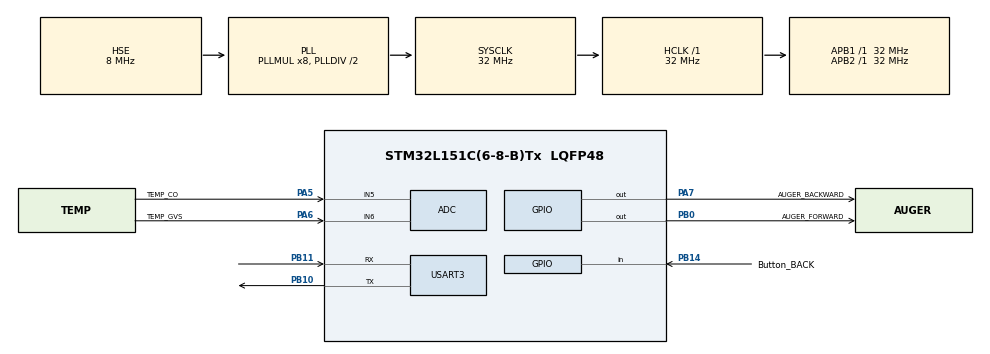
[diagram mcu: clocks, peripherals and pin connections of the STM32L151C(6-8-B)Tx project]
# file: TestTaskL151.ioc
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ADC.Channel-0\#ChannelRegularConversion=ADC_CHANNEL_5
ADC.Channel-1\#ChannelRegularConversion=ADC_CHANNEL_6
ADC.ContinuousConvMode=ENABLE
ADC.DMAContinuousRequests=DISABLE
ADC.NbrOfConversion=2
ADC.NbrOfConversionFlag=1
ADC.Rank-0\#ChannelRegularConversion=1
ADC.Rank-1\#ChannelRegularConversion=2
ADC.SamplingTime-0\#ChannelRegularConversion=ADC_SAMPLETIME_384CYCLES
ADC.SamplingTime-1\#ChannelRegularConversion=ADC_SAMPLETIME_384CYCLES
ADC.ScanConvMode=ADC_SCAN_ENABLE
Dma.ADC.0.Direction=DMA_PERIPH_TO_MEMORY
Dma.ADC.0.Instance=DMA1_Channel1
Dma.ADC.0.MemDataAlignment=DMA_MDATAALIGN_HALFWORD
Dma.ADC.0.MemInc=DMA_MINC_ENABLE
Dma.ADC.0.Mode=DMA_NORMAL
Dma.ADC.0.PeriphDataAlignment=DMA_PDATAALIGN_HALFWORD
Dma.ADC.0.PeriphInc=DMA_PINC_DISABLE
Dma.ADC.0.Priority=DMA_PRIORITY_LOW
Dma.Request0=ADC
FREERTOS.HEAP_NUMBER=1
FREERTOS.INCLUDE_uxTaskGetStackHighWaterMark=0
FREERTOS.INCLUDE_vTaskDelete=0
FREERTOS.Tasks01=defaultTask,0,64,StartDefaultTask,Default,NULL,Dynamic,NULL,NULL
FREERTOS.configENABLE_BACKWARD_COMPATIBILITY=1
FREERTOS.configGENERATE_RUN_TIME_STATS=0
FREERTOS.configLIBRARY_LOWEST_INTERRUPT_PRIORITY=8
FREERTOS.configMAX_TASK_NAME_LEN=12
FREERTOS.configMINIMAL_STACK_SIZE=64
FREERTOS.configRECORD_STACK_HIGH_ADDRESS=0
FREERTOS.configTOTAL_HEAP_SIZE=2048
FREERTOS.configUSE_MUTEXES=0
FREERTOS.configUSE_NEWLIB_REENTRANT=1
FREERTOS.configUSE_TASK_NOTIFICATIONS=1
FREERTOS.configUSE_TRACE_FACILITY=0
Mcu.Family=STM32L1
Mcu.Name=STM32L151C(6-8-B)Tx
Mcu.Package=LQFP48
NVIC.DMA1_Channel1_IRQn=true\:5\:0\:false\:false\:true\:true\:false\:true\:true
NVIC.PriorityGroup=NVIC_PRIORITYGROUP_4
NVIC.TIM2_IRQn=true\:15\:0\:false\:false\:true\:false\:false\:true\:true
NVIC.TimeBase=TIM2_IRQn
NVIC.TimeBaseIP=TIM2
PA13.Mode=Serial_Wire
PA13.Signal=SYS_JTMS-SWDIO
PA14.Mode=Serial_Wire
PA14.Signal=SYS_JTCK-SWCLK
PA5.GPIO_Label=TEMP_CO
PA5.Mode=IN5
PA5.Signal=ADC_IN5
PA6.GPIO_Label=TEMP_GVS
PA6.Mode=IN6
PA6.Signal=ADC_IN6
PA7.GPIO_Label=AUGER_BACKWARD
PA7.GPIO_PuPd=GPIO_PULLDOWN
PA7.GPIO_Speed=GPIO_SPEED_FREQ_VERY_HIGH
PA7.PinState=GPIO_PIN_RESET
PA7.Signal=GPIO_Output
PB0.GPIO_Label=AUGER_FORWARD
PB0.GPIO_PuPd=GPIO_PULLDOWN
PB0.GPIO_Speed=GPIO_SPEED_FREQ_VERY_HIGH
PB0.PinState=GPIO_PIN_RESET
PB0.Signal=GPIO_Output
PB10.Mode=Asynchronous
PB10.Signal=USART3_TX
PB11.Mode=Asynchronous
PB11.Signal=USART3_RX
PB14.GPIO_Label=Button_BACK
PB14.GPIO_PuPd=GPIO_PULLDOWN
PB14.Signal=GPIO_Input
PH0-OSC_IN.Mode=HSE-External-Oscillator
PH0-OSC_IN.Signal=RCC_OSC_IN
PH1-OSC_OUT.Mode=HSE-External-Oscillator
PH1-OSC_OUT.Signal=RCC_OSC_OUT
ProjectManager.HeapSize=0x2000
ProjectManager.StackSize=0x4000
ProjectManager.TargetToolchain=STM32CubeIDE
RCC.48MHZClocksFreq_Value=32000000
RCC.AHBFreq_Value=32000000
RCC.APB1Freq_Value=32000000
RCC.APB1TimFreq_Value=32000000
RCC.APB2Freq_Value=32000000
RCC.APB2TimFreq_Value=32000000
RCC.HCLKFreq_Value=32000000
RCC.HSE_VALUE=8000000
RCC.HSI_VALUE=16000000
RCC.LSE_VALUE=32768
RCC.MSI_VALUE=2097000
RCC.PLLMUL=RCC_PLL_MUL8
RCC.PLLSourceVirtual=RCC_PLLSOURCE_HSE
RCC.SYSCLKFreq_VALUE=32000000
RCC.SYSCLKSource=RCC_SYSCLKSOURCE_PLLCLK
RCC.VCOOutputFreq_Value=64000000
USART3.VirtualMode=VM_ASYNC
VP_FREERTOS_VS_CMSIS_V1.Mode=CMSIS_V1
VP_SYS_VS_tim2.Mode=TIM2
board=custom

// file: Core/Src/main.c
/* USER CODE BEGIN Header */
/**
  ******************************************************************************
  * @file           : main.c
  * @brief          : Main program body
  ******************************************************************************
  * @attention
  *
  * Copyright (c) 2023 STMicroelectronics.
  * All rights reserved.
  *
  * This software is licensed under terms that can be found in the LICENSE file
  * in the root directory of this software component.
  * If no LICENSE file comes with this software, it is provided AS-IS.
  *
  ******************************************************************************
  */
/* USER CODE END Header */
#include "main.h"
#include "cmsis_os.h"
#include "adc.h"
#include "dma.h"
#include "usart.h"
#include "gpio.h"

/* USER CODE BEGIN Includes */
#include "General.h"
/* USER CODE END Includes */

void SystemClock_Config(void);
void MX_FREERTOS_Init(void);

int main(void)
{

  /* MCU Configuration--------------------------------------------------------*/

  /* Reset of all peripherals, Initializes the Flash interface and the Systick. */
  HAL_Init();

  /* Configure the system clock */
  SystemClock_Config();

  /* Initialize all configured peripherals */
  MX_GPIO_Init();
  MX_DMA_Init();
  MX_ADC_Init();
  MX_USART3_UART_Init();
  /* USER CODE BEGIN 2 */
  if (SysIni()==1)
  {
  /* USER CODE END 2 */

  /* Call init function for freertos objects (in freertos.c) */
  MX_FREERTOS_Init();

  /* Start scheduler */
  osKernelStart();

  /* We should never get here as control is now taken by the scheduler */
  /* Infinite loop */
  }
  while (1)
  {

  }
}

void SystemClock_Config(void)
{
  RCC_OscInitTypeDef RCC_OscInitStruct = {0};
  RCC_ClkInitTypeDef RCC_ClkInitStruct = {0};

  /** Configure the main internal regulator output voltage
  */
  __HAL_PWR_VOLTAGESCALING_CONFIG(PWR_REGULATOR_VOLTAGE_SCALE1);

  /** Initializes the RCC Oscillators according to the specified parameters
  * in the RCC_OscInitTypeDef structure.
  */
  RCC_OscInitStruct.OscillatorType = RCC_OSCILLATORTYPE_HSI|RCC_OSCILLATORTYPE_HSE;
  RCC_OscInitStruct.HSEState = RCC_HSE_ON;
  RCC_OscInitStruct.HSIState = RCC_HSI_ON;
  RCC_OscInitStruct.HSICalibrationValue = RCC_HSICALIBRATION_DEFAULT;
  RCC_OscInitStruct.PLL.PLLState = RCC_PLL_ON;
  RCC_OscInitStruct.PLL.PLLSource = RCC_PLLSOURCE_HSE;
  RCC_OscInitStruct.PLL.PLLMUL = RCC_PLL_MUL8;
  RCC_OscInitStruct.PLL.PLLDIV = RCC_PLL_DIV2;
  if (HAL_RCC_OscConfig(&RCC_OscInitStruct) != HAL_OK)
  {
    Error_Handler();
  }

  /** Initializes the CPU, AHB and APB buses clocks
  */
  RCC_ClkInitStruct.ClockType = RCC_CLOCKTYPE_HCLK|RCC_CLOCKTYPE_SYSCLK
                              |RCC_CLOCKTYPE_PCLK1|RCC_CLOCKTYPE_PCLK2;
  RCC_ClkInitStruct.SYSCLKSource = RCC_SYSCLKSOURCE_PLLCLK;
  RCC_ClkInitStruct.AHBCLKDivider = RCC_SYSCLK_DIV1;
  RCC_ClkInitStruct.APB1CLKDivider = RCC_HCLK_DIV1;
  RCC_ClkInitStruct.APB2CLKDivider = RCC_HCLK_DIV1;

  if (HAL_RCC_ClockConfig(&RCC_ClkInitStruct, FLASH_LATENCY_1) != HAL_OK)
  {
    Error_Handler();
  }
}

void HAL_TIM_PeriodElapsedCallback(TIM_HandleTypeDef *htim)
{
  if (htim->Instance == TIM2) {
    HAL_IncTick();
  }
}

void Error_Handler(void)
{
  __disable_irq();
  while (1)
  {
  }
}

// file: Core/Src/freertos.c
/* USER CODE BEGIN Header */
/**
  ******************************************************************************
  * File Name          : freertos.c
  * Description        : Code for freertos applications
  ******************************************************************************
  * @attention
  *
  * Copyright (c) 2023 STMicroelectronics.
  * All rights reserved.
  *
  * This software is licensed under terms that can be found in the LICENSE file
  * in the root directory of this software component.
  * If no LICENSE file comes with this software, it is provided AS-IS.
  *
  ******************************************************************************
  */
/* USER CODE END Header */

#include "FreeRTOS.h"
#include "task.h"
#include "main.h"
#include "cmsis_os.h"

//osThreadId defaultTaskHandle;

//void StartDefaultTask(void const * argument);

void MX_FREERTOS_Init(void); /* (MISRA C 2004 rule 8.1) */

/* GetIdleTaskMemory prototype (linked to static allocation support) */
void vApplicationGetIdleTaskMemory( StaticTask_t **ppxIdleTaskTCBBuffer, StackType_t **ppxIdleTaskStackBuffer, uint32_t *pulIdleTaskStackSize );

/* USER CODE BEGIN GET_IDLE_TASK_MEMORY */
static StaticTask_t xIdleTaskTCBBuffer;
static StackType_t xIdleStack[configMINIMAL_STACK_SIZE];

void vApplicationGetIdleTaskMemory( StaticTask_t **ppxIdleTaskTCBBuffer, StackType_t **ppxIdleTaskStackBuffer, uint32_t *pulIdleTaskStackSize )
{
  *ppxIdleTaskTCBBuffer = &xIdleTaskTCBBuffer;
  *ppxIdleTaskStackBuffer = &xIdleStack[0];
  *pulIdleTaskStackSize = configMINIMAL_STACK_SIZE;
  /* place for user code */
}
/* USER CODE END GET_IDLE_TASK_MEMORY */

void MX_FREERTOS_Init(void) {

  /* Create the thread(s) */
  /* definition and creation of defaultTask */
//  osThreadDef(defaultTask, StartDefaultTask, osPriorityNormal, 0, 64);
//  defaultTaskHandle = osThreadCreate(osThread(defaultTask), NULL);

}

//void StartDefaultTask(void const * argument)
//{
//  /* USER CODE BEGIN StartDefaultTask */
//  /* Infinite loop */
//  for(;;)
//  {
//    osDelay(10000);
//  }
//  /* USER CODE END StartDefaultTask */
//}
